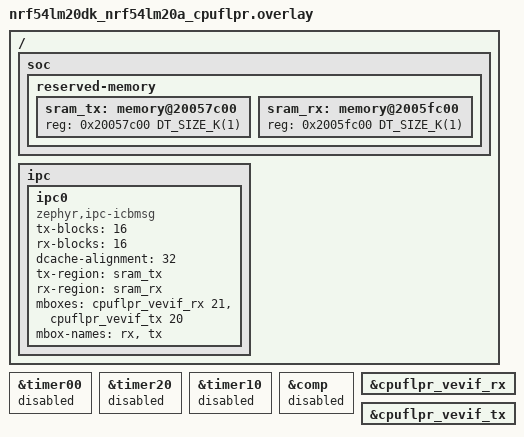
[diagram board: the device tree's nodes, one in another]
/*
 * Copyright (c) 2026 Nordic Semiconductor ASA
 *
 * SPDX-License-Identifier: Apache-2.0
 */

dut_timer0: &timer00 {
	status = "reserved";
};

dut_timer1: &timer20 {
	status = "reserved";
};

dut_timer2: &timer10 {
	status = "reserved";
};

&comp {
	status = "reserved";
};

/ {
	soc {
		reserved-memory {
			#address-cells = <1>;
			#size-cells = <1>;

			sram_tx: memory@20057c00 {
				reg = <0x20057c00 DT_SIZE_K(1)>;
			};

			sram_rx: memory@2005fc00 {
				reg = <0x2005fc00 DT_SIZE_K(1)>;
			};
		};
	};

	ipc {
		ipc0: ipc0 {
			compatible = "zephyr,ipc-icbmsg";
			tx-blocks = <16>;
			rx-blocks = <16>;
			dcache-alignment = <32>;
			tx-region = <&sram_tx>;
			rx-region = <&sram_rx>;
			mboxes = <&cpuflpr_vevif_rx 21>, <&cpuflpr_vevif_tx 20>;
			mbox-names = "rx", "tx";
			status = "okay";
		};
	};
};

&cpuflpr_vevif_rx {
	status = "okay";
};

&cpuflpr_vevif_tx {
	status = "okay";
};
